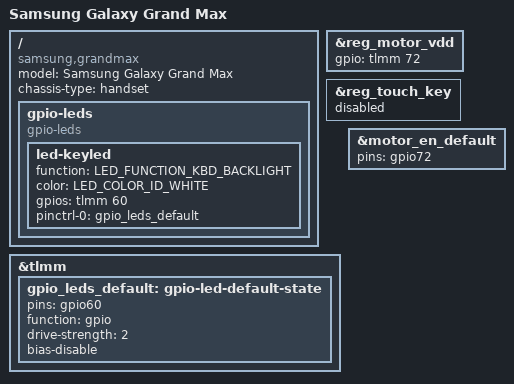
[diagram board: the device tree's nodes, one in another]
/dts-v1/;
#include "msm8916-samsung-e2015-common.dtsi"
#include <dt-bindings/leds/common.h>
/ {
	model = "Samsung Galaxy Grand Max";
	compatible = "samsung,grandmax", "qcom,msm8916";
	chassis-type = "handset";
	/delete-node/ gpio-hall-sensor;
	/delete-node/ i2c-nfc;
	/delete-node/ i2c-tkey;
	gpio-leds {
		compatible = "gpio-leds";
		led-keyled {
			function = LED_FUNCTION_KBD_BACKLIGHT;
			color = <LED_COLOR_ID_WHITE>;
			gpios = <&tlmm 60 GPIO_ACTIVE_HIGH>;
			pinctrl-names = "default";
			pinctrl-0 = <&gpio_leds_default>;
		};
	};
};
&reg_motor_vdd {
	gpio = <&tlmm 72 GPIO_ACTIVE_HIGH>;
};
&reg_touch_key {
	status = "disabled";
};
&tlmm {
	gpio_leds_default: gpio-led-default-state {
		pins = "gpio60";
		function = "gpio";
		drive-strength = <2>;
		bias-disable;
	};
};
&motor_en_default {
	pins = "gpio72";
};
